# f29h85x_memss_l_config_regs register map
Vendor: Texas Instruments
Peripheral module from a debugger description file (folder HSM).
Registers are 32-bit, read-write, no defined reset value unless marked. A register's access mark holds for its fields unless they carry their own. Offsets are as the file gives them; lines under a group give offsets from that group; [hi:lo] are bit positions; {n}, {i} and the like mark numbered series; 'fields as' and 'values as' point back to an identical list; <NAME> marks a mode.

## MEMSS_L_CONFIG_REGS — MEMSS L CONFIG Registers
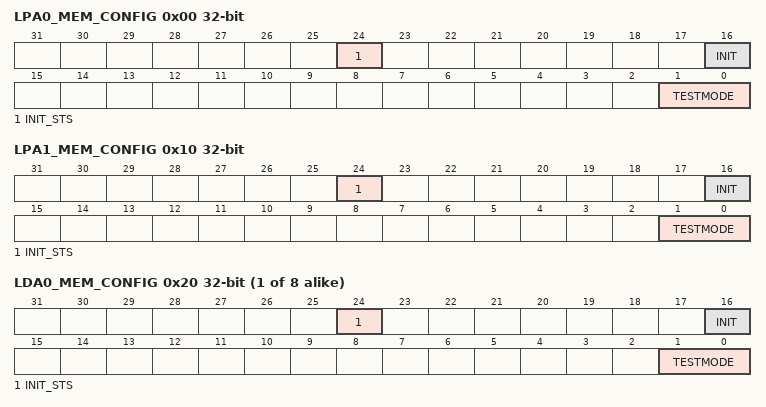
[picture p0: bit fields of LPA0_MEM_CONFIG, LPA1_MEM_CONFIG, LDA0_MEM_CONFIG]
0x00 LPA0_MEM_CONFIG access per field — LPA0 Memory Configuration Register
  [24] INIT_STS ro — LPA0 INIT status
  [16] INIT rw — Triggers memory Initilization
  [1:0] TESTMODE rw — LPA0 Test Mode
0x04 LPA0_MEM_CONFIG_LOCK — Temporary Lock for LPA0 Memory Configuration Register
  [0] LPA0_MEM_CONFIG — Temporary Lock
0x08 LPA0_MEM_CONFIG_COMMIT — Permament Lock for LPA0 Memory Configuration Register
  [0] LPA0_MEM_CONFIG_LOCK — Permanent Commit
0x10 LPA1_MEM_CONFIG access per field — LPA1 Memory Configuration Register
  [24] INIT_STS ro — LPA1 INIT status
  [16] INIT rw — Triggers memory Initilization
  [1:0] TESTMODE rw — LPA1 Test Mode
0x14 LPA1_MEM_CONFIG_LOCK — Temporary Lock for LPA1 Memory Configuration Register
  [0] LPA1_MEM_CONFIG — Temporary Lock
0x18 LPA1_MEM_CONFIG_COMMIT — Permament Lock for LPA1 Memory Configuration Register
  [0] LPA1_MEM_CONFIG_LOCK — Permanent Commit
{0x20+0x10*i} LDA{i}_MEM_CONFIG access per field (i=0..7) — LDA{i} Memory Configuration Register
  [24] INIT_STS ro — LDA{i} INIT status
  [16] INIT rw — Triggers memory Initilization
  [1:0] TESTMODE rw — LDA{i} Test Mode
{0x24+0x10*i} LDA{i}_MEM_CONFIG_LOCK (i=0..7) — Temporary Lock for LDA{i} Memory Configuration Register
  [0] LDA{i}_MEM_CONFIG — Temporary Lock
{0x28+0x10*i} LDA{i}_MEM_CONFIG_COMMIT (i=0..7) — Permament Lock for LDA{i} Memory Configuration Register
  [0] LDA{i}_MEM_CONFIG_LOCK — Permanent Commit
